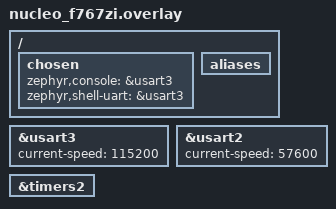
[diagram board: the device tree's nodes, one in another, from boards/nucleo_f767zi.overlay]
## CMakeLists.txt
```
# SPDX-License-Identifier: Apache-2.0

cmake_minimum_required(VERSION 3.20.0)
find_package(Zephyr REQUIRED HINTS $ENV{ZEPHYR_BASE})
project(EdgeSystemController)

set(BOARD_FLASH_RUNNER jlink)

FILE(GLOB app_sources src/*.c)
target_sources(app PRIVATE ${app_sources})
```

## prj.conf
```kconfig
CONFIG_STDOUT_CONSOLE=y

CONFIG_LOG=y
CONFIG_LOG_MODE_IMMEDIATE=y
CONFIG_LOG_PRINTK=y

# Kernel Configuration
CONFIG_MULTITHREADING=y
CONFIG_NUM_PREEMPT_PRIORITIES=15
CONFIG_MAIN_STACK_SIZE=2048
CONFIG_SYSTEM_WORKQUEUE_STACK_SIZE=2048
CONFIG_IDLE_STACK_SIZE=512

# Thread Configuration
CONFIG_THREAD_MONITOR=y
CONFIG_THREAD_NAME=y
CONFIG_THREAD_RUNTIME_STATS=y

# Message Queue Configuration
CONFIG_KERNEL_MEM_POOL=y

# Pipe Configuration  

# Ring Buffer Configuration
CONFIG_RING_BUFFER=y


# Memory Management
CONFIG_HEAP_MEM_POOL_SIZE=262144
CONFIG_DYNAMIC_THREAD=y

# Serial/UART for MAVLink
CONFIG_SERIAL=y
CONFIG_UART_INTERRUPT_DRIVEN=y
CONFIG_UART_LINE_CTRL=y

CONFIG_GPIO=y

# Debug Options
CONFIG_DEBUG=y
CONFIG_ASSERT=y
```

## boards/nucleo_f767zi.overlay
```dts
/*
 * Device Tree Overlay for STM32F767ZI Nucleo Board
 * Edge AI System Controller
 */


/ {
	chosen {
		zephyr,console = &usart3;
		zephyr,shell-uart = &usart3;
	};

	aliases {

	};
};

/* UART3 for console/debug */
&usart3 {
	status = "okay";
	current-speed = <115200>;
};

/* UART2 for MAVLink communication */
&usart2 {
	status = "okay";
	current-speed = <57600>;
};

&timers2 {

};
```

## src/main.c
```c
/**
 * SPDX-License-Identifier: Apache-2.0
 */

#include <zephyr/kernel.h>
#include <inttypes.h>
#include <zephyr/logging/log.h>

#include "system_config.h"
#include "device_fsm.h"
#include "common_types.h"
#include "ipc_config.h"
#include "thread_interface.h"

#define LOG_LEVEL CONFIG_MAIN_LOG_LEVEL
LOG_MODULE_REGISTER(main);

/*
 * GLOBAL STATE VARIABLES
 */
system_state_t system_state = INIT;
/* Global System State */
thread_health_t g_health = {0};
volatile bool g_system_running = false;


/**
 * IPC PRIMITIVES DEFINITIONS
 */

/* Message Queues */
K_MSGQ_DEFINE(sys_cmd_queue, sizeof(sys_command_t), SYS_CMD_QUEUE_SIZE, 4);
K_MSGQ_DEFINE(mavlink_tx_queue, sizeof(telemetry_data_t), MAVLINK_TX_QUEUE_SIZE, 4);

/**
 * THREAD DEFINITIONS
 */
/* Define Thread Stacks */
K_THREAD_STACK_DEFINE(mavlink_stack, MAVLINK_STACK_SIZE);
K_THREAD_STACK_DEFINE(sys_mgr_stack, SYS_MGR_STACK_SIZE);
K_THREAD_STACK_DEFINE(health_stack, HEALTH_STACK_SIZE);

/* Thread Control Blocks */
static struct k_thread mavlink_thread_data;
static struct k_thread sys_mgr_thread_data;
static struct k_thread health_thread_data;

/* Thread IDs */
static k_tid_t mavlink_tid;
static k_tid_t sys_mgr_tid;
static k_tid_t health_tid;

#define SLEEP_TIME_MS   1000

int main(void)
{
	LOG_INF("  Edge AI Vision System Controller\n");
	LOG_INF("  Platform: STM32F767ZI\n");
	LOG_INF("  Threads: 6 (SysMgr, MAVLink, AI, Video, GCS, Health)\n\n");

	/* All threads are auto-started by K_THREAD_DEFINE */
	/* Create MAVLink Thread */
    mavlink_tid = k_thread_create(&mavlink_thread_data, mavlink_stack,
                                   K_THREAD_STACK_SIZEOF(mavlink_stack),
                                   mavlink_thread,
                                   NULL, NULL, NULL,
                                   MAVLINK_PRIORITY, 0, K_NO_WAIT);
    k_thread_name_set(mavlink_tid, "mavlink");
    LOG_INF("Created: MAVLink Thread (Priority %d)", MAVLINK_PRIORITY);
    
    /* Create SysMgr Thread */
    sys_mgr_tid = k_thread_create(&sys_mgr_thread_data, sys_mgr_stack,
                                  K_THREAD_STACK_SIZEOF(sys_mgr_stack),
                                  sys_mgr_thread,
                                  NULL, NULL, NULL,
                                  SYS_MGR_PRIORITY, 0, K_NO_WAIT);
    k_thread_name_set(sys_mgr_tid, "sys_mgr");
    LOG_INF("Created: SysMgr Thread (Priority %d)", SYS_MGR_PRIORITY);
    
    /* Create Health Monitor Thread */
    health_tid = k_thread_create(&health_thread_data, health_stack,
                                  K_THREAD_STACK_SIZEOF(health_stack),
                                  health_thread,
                                  NULL, NULL, NULL,
                                  HEALTH_PRIORITY, 0, K_NO_WAIT);
    k_thread_name_set(health_tid, "health");
    LOG_INF("Created: Health Thread (Priority %d)", HEALTH_PRIORITY);

	while (1) {
		k_msleep(SLEEP_TIME_MS);
	}

	return 0;
}
```

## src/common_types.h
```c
/**
 * @file common_types.h
 * @brief Common data structures used across threads
 */

#ifndef COMMON_TYPES_H_
#define COMMON_TYPES_H_

#include <stdint.h>
#include <stdbool.h>
#include <zephyr/sys/atomic.h>
#include "system_config.h"

/**
 * COMMAND MESSAGES
 */

/* System Command Types */
typedef enum {
    CMD_STOP,
    CMD_START,
    CMD_STREAM_START,
    CMD_STREAM_STOP,
    CMD_SHUTDOWN,
    CMD_ERROR
} system_cmd_t;

/* System Command Structure */
typedef struct {
    system_cmd_t command;   /* Command type */
    uint32_t param;         /* Command parameter */
} sys_command_t;

/* Telemetry Data Structure */
typedef struct {
    float lat;          /* Latitude in degrees */
    float lon;          /* Longitude in degrees */
    float alt;          /* Altitude in meters */
    float roll;         /* Roll angle in degrees */
    float pitch;        /* Pitch angle in degrees */
    float yaw;          /* Yaw angle in degrees */
    uint32_t timestamp; /* System timestamp in ms */
} telemetry_data_t;


/* Thread Heartbeat Structure */
typedef struct {
    atomic_t mavlink_heartbeat;
    atomic_t sys_mgr_heartbeat;
} thread_health_t;

/* Thread IDs for health monitoring */
#define THREAD_SYS_MGR  0
#define THREAD_MAVLINK  1
#define THREAD_AI       2
#define THREAD_GCS      3
#define THREAD_HEALTH   4
#define NUM_THREADS     5

#endif /* COMMON_TYPES_H_ */
```

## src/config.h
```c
#ifndef CONFIG_H_
#define CONFIG_H_

#include <stdint.h>

typedef struct dev_data
{
    uint8_t _reserved;
} dev_data_t;

#endif /* CONFIG_H_ */
```

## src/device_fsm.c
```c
/**
 * @file device_fsm.c
 * @brief Internal device finite state machine implementation
 */ 
#include <zephyr/logging/log.h>

#include "device_fsm.h"

#define LOG_LEVEL CONFIG_DEVICE_SM_LOG_LEVEL
LOG_MODULE_REGISTER(device_sm);

static system_state_t current_state = INIT;
static system_state_t previous_state = INIT;

/**
 * @brief State machine initialization
 */
void fsm_init(void)
{
    current_state = INIT;
}

/**
 * @brief Get the current state of the state machine
 * @return The current system state
 */
system_state_t fsm_get_current_state(void)
{
    return current_state;
}

/**
 * @brief Get the previous state of the state machine
 * @param  NIL
 * @return The previous system state
 */
system_state_t fsm_get_previous_state(void)
{
    return previous_state;
}

/** 
 * @brief State transition function
 * @param event The event triggering the state transition
 */
void fsm_event_handler(system_event_t event) 
{
    previous_state = current_state;
    
    switch (current_state) {
        case INIT:
            if (event == EVENT_INIT_DONE) {
                current_state = IDLE;
                LOG_INF("Transition: INIT -> IDLE");
            }
            else if (event == EVENT_INIT_FAILED) {
                current_state = FAULT;
                LOG_INF("Transition: INIT -> FAULT");
            }
            break;
        case IDLE:
            if (event == EVENT_CMD_START) {
                current_state = ACTIVE;
                LOG_INF("Transition: IDLE -> ACTIVE");
            } 
            else if (event == EVENT_CMD_SHUTDOWN) {
                current_state = SHUTDOWN;
                LOG_INF("Transition: IDLE -> SHUTDOWN");
            }
            else if (event == EVENT_FAULT_DETECTED) {
                current_state = FAULT;
                LOG_INF("Transition: IDLE -> FAULT");
            }
            break;
        case ACTIVE:
            if (event == EVENT_STREAM_STARTED) {
                current_state = STREAMING;
                LOG_INF("Transition: ACTIVE -> STREAMING");
            } 
            else if (event == EVENT_CMD_STOP) {
                current_state = IDLE;
                LOG_INF("Transition: ACTIVE -> IDLE");
            }
            else if (event == EVENT_CMD_SHUTDOWN) {
                current_state = SHUTDOWN;
                LOG_INF("Transition: ACTIVE -> SHUTDOWN");
            }
            else if (event == EVENT_FAULT_DETECTED) {
                current_state = FAULT;
                LOG_INF("Transition: ACTIVE -> FAULT");
            }
            break;
        case STREAMING:
            if (event == EVENT_STREAM_DEGRADED) {
                current_state = DEGRADED;
                LOG_INF("Transition: STREAMING -> DEGRADED");
            } 
            else if (event == EVENT_STREAM_STOPPED) {
                current_state = ACTIVE;
                LOG_INF("Transition: STREAMING -> ACTIVE");
            }
            else if (event == EVENT_CMD_SHUTDOWN) {
                current_state = SHUTDOWN;
                LOG_INF("Transition: STREAMING -> SHUTDOWN");
            }
            else if (event == EVENT_FAULT_DETECTED) {
                current_state = FAULT;
                LOG_INF("Transition: STREAMING -> FAULT");
            }
            break;
        case DEGRADED:
            if (event == EVENT_STREAM_RECOVERED) {
                current_state = STREAMING;
                LOG_INF("Transition: DEGRADED -> STREAMING");
            } 
            else if (event == EVENT_STREAM_STOPPED) {
                current_state = ACTIVE;
                LOG_INF("Transition: DEGRADED -> ACTIVE");
            }
            else if (event == EVENT_CMD_SHUTDOWN) {
                current_state = SHUTDOWN;
                LOG_INF("Transition: DEGRADED -> SHUTDOWN");
            }
            else if (event == EVENT_FAULT_DETECTED) {
                current_state = FAULT;
                LOG_INF("Transition: DEGRADED -> FAULT");
            }
            break;     
        case FAULT:
            if (event == EVENT_FAULT_RECOVERED) {
                current_state = IDLE;
                LOG_INF("Transition: FAULT -> IDLE");
            }
            break;
        case SHUTDOWN:
            // No transitions out of SHUTDOWN in this simple model
            break;
        default:
            LOG_INF("Unknown state: %d", current_state);
            break;
    }
}
```

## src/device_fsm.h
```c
/**
 * @file device_fsm.h
 * @brief Internal device finite state machine definitions
 */

#ifndef DEVICE_FSM_H_
#define DEVICE_FSM_H_

/* List of end node states */
typedef enum {
    INIT, 
    IDLE,
    ACTIVE,
    STREAMING,
    DEGRADED,
    SHUTDOWN,
    FAULT
} system_state_t;

// Define events
typedef enum {
    EVENT_INIT_DONE,
    EVENT_INIT_FAILED,
    EVENT_CMD_START,
    EVENT_CMD_STOP,
    EVENT_CMD_SHUTDOWN,
    EVENT_STREAM_STARTED,
    EVENT_STREAM_STOPPED,
    EVENT_STREAM_DEGRADED,
    EVENT_STREAM_RECOVERED,
    EVENT_FAULT_DETECTED,
    EVENT_FAULT_RECOVERED
} system_event_t;

void fsm_init(void);
system_state_t fsm_get_current_state(void);
system_state_t fsm_get_previous_state(void);
void fsm_event_handler(system_event_t event);

#endif /* DEVICE_FSM_H_ */
```

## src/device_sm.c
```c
// State machine includes
//#include <zephyr/smf.h>
#include <zephyr/logging/log.h>

#include "device_sm.h"

#define LOG_LEVEL CONFIG_DEVICE_SM_LOG_LEVEL
LOG_MODULE_REGISTER(device_sm);

static state_t current_state = INIT;
static state_t previous_state = INIT;

void fsm_init(void)
{
    current_state = INIT;
}

state_t fsm_get_current_state(void)
{
    return current_state;
}

state_t fsm_get_previous_state(void)
{
    return previous_state;
}


// State transition function
void fsm_event_handler(event_t event) 
{
    previous_state = current_state;
    
    switch (current_state) {
        case INIT:
            if (event == EVENT_INIT_DONE) {
                current_state = IDLE;
                LOG_INF("Transition: INIT -> IDLE");
            }
            else if (event == EVENT_INIT_FAILED) {
                current_state = FAULT;
                LOG_INF("Transition: INIT -> FAULT");
            }
            break;
        case IDLE:
            if (event == EVENT_CMD_START) {
                current_state = ACTIVE;
                LOG_INF("Transition: IDLE -> ACTIVE");
            } 
            else if (event == EVENT_CMD_SHUTDOWN) {
                current_state = SHUTDOWN;
                LOG_INF("Transition: IDLE -> SHUTDOWN");
            }
            else if (event == EVENT_FAULT_DETECTED) {
                current_state = FAULT;
                LOG_INF("Transition: IDLE -> FAULT");
            }
            break;
        case ACTIVE:
            if (event == EVENT_STREAM_STARTED) {
                current_state = STREAMING;
                LOG_INF("Transition: ACTIVE -> STREAMING");
            } 
            else if (event == EVENT_CMD_STOP) {
                current_state = IDLE;
                LOG_INF("Transition: ACTIVE -> IDLE");
            }
            else if (event == EVENT_CMD_SHUTDOWN) {
                current_state = SHUTDOWN;
                LOG_INF("Transition: ACTIVE -> SHUTDOWN");
            }
            else if (event == EVENT_FAULT_DETECTED) {
                current_state = FAULT;
                LOG_INF("Transition: ACTIVE -> FAULT");
            }
            break;
        case STREAMING:
            if (event == EVENT_STREAM_DEGRADED) {
                current_state = DEGRADED;
                LOG_INF("Transition: STREAMING -> DEGRADED");
            } 
            else if (event == EVENT_STREAM_STOPPED) {
                current_state = ACTIVE;
                LOG_INF("Transition: STREAMING -> ACTIVE");
            }
            else if (event == EVENT_CMD_SHUTDOWN) {
                current_state = SHUTDOWN;
                LOG_INF("Transition: STREAMING -> SHUTDOWN");
            }
            else if (event == EVENT_FAULT_DETECTED) {
                current_state = FAULT;
                LOG_INF("Transition: STREAMING -> FAULT");
            }
            break;
        case DEGRADED:
            if (event == EVENT_STREAM_RECOVERED) {
                current_state = STREAMING;
                LOG_INF("Transition: DEGRADED -> STREAMING");
            } 
            else if (event == EVENT_STREAM_STOPPED) {
                current_state = ACTIVE;
                LOG_INF("Transition: DEGRADED -> ACTIVE");
            }
            else if (event == EVENT_CMD_SHUTDOWN) {
                current_state = SHUTDOWN;
                LOG_INF("Transition: DEGRADED -> SHUTDOWN");
            }
            else if (event == EVENT_FAULT_DETECTED) {
                current_state = FAULT;
                LOG_INF("Transition: DEGRADED -> FAULT");
            }
            break;     
        case FAULT:
            if (event == EVENT_FAULT_RECOVERED) {
                current_state = IDLE;
                LOG_INF("Transition: FAULT -> IDLE");
            }
            break;
        case SHUTDOWN:
            LOG_INF("System in SHUTDOWN state - restart required");
            break;
        default:
            LOG_INF("Unknown state: %d", current_state);
            break;
    }
}
```

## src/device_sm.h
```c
#ifndef DEVICE_SM_H_
#define DEVICE_SM_H_

/* List of end node states */
typedef enum {
    INIT, 
    IDLE,
    ACTIVE,
    STREAMING,
    DEGRADED,
    SHUTDOWN,
    FAULT
} state_t;

// Define events
typedef enum {
    EVENT_INIT_DONE,
    EVENT_INIT_FAILED,
    EVENT_CMD_START,
    EVENT_CMD_STOP,
    EVENT_CMD_SHUTDOWN,
    EVENT_STREAM_STARTED,
    EVENT_STREAM_STOPPED,
    EVENT_STREAM_DEGRADED,
    EVENT_STREAM_RECOVERED,
    EVENT_FAULT_DETECTED,
    EVENT_FAULT_RECOVERED
} event_t;

void fsm_init(void);
state_t fsm_get_current_state(void);
state_t fsm_get_previous_state(void);
void fsm_event_handler(event_t event);

#endif /* DEVICE_SM_H_ */
```

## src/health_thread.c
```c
/**
 * @file health_thread.c
 * @brief Health monitoring thread implementation
 * @details Monitors all threads and triggers recovery on failures
 */

#include <zephyr/kernel.h>
#include <zephyr/drivers/gpio.h>
#include <zephyr/logging/log.h>

#include "system_config.h"
#include "common_types.h"
#include "ipc_config.h"

#define LOG_LEVEL CONFIG_HEALTH_THREAD_LOG_LEVEL
LOG_MODULE_REGISTER(health_thread);

#define LED0_NODE DT_ALIAS(led0)

static const struct gpio_dt_spec led = GPIO_DT_SPEC_GET(LED0_NODE, gpios);

/**
 * @brief Health Monitor Thread Main Loop
 * @details
 * - Checks all thread heartbeats every 500ms
 * - Detects thread hangs/failures
 * - Triggers recovery via system commands
 * 
 * @param p1 Unused parameter
 * @param p2 Unused parameter
 * @param p3 Unused parameter
 */
void health_thread(void *p1, void *p2, void *p3)
{
    static thread_health_t last_health = {0};
    sys_command_t error_cmd;
    uint32_t check_count = 0;
    
    ARG_UNUSED(p1);
    ARG_UNUSED(p2);
    ARG_UNUSED(p3);
    
    LOG_INF("[Health] Thread started");
    LOG_INF("[Health] Monitoring period: %dms", HEALTH_CHECK_PERIOD_MS);

    int ret;
	bool led_state = true;

	if (!gpio_is_ready_dt(&led)) {
		LOG_ERR("LED device not ready");
	} else {
        ret = gpio_pin_configure_dt(&led, GPIO_OUTPUT_ACTIVE);
        if (ret < 0) {
            LOG_ERR("Error configuring LED pin");
        }
    }

    while (1) {
        /* Wait for health check interval */
        k_msleep(HEALTH_CHECK_PERIOD_MS);
        check_count++;
        
		ret = gpio_pin_toggle_dt(&led);
		if (ret < 0) {
			LOG_ERR("Error toggling LED pin");
		}
		led_state = !led_state;


        bool all_healthy = true;
        
        // Atomic snapshot ensures consistent view of all counters
        atomic_val_t mavlink_hb = atomic_get(&g_health.mavlink_heartbeat);
        atomic_val_t last_mavlink_hb = atomic_get(&last_health.mavlink_heartbeat);  
        
        /* Check MAVLink thread */
        if (mavlink_hb == last_mavlink_hb) {
            LOG_ERR("[Health] ERROR: MAVLink thread HUNG!");
            all_healthy = false;
        }

        atomic_val_t sys_mgr_hb = atomic_get(&g_health.sys_mgr_heartbeat);
        atomic_val_t last_sys_mgr_hb = atomic_get(&last_health.sys_mgr_heartbeat);
        
        /* Check SysMgr thread */
        if (sys_mgr_hb == last_sys_mgr_hb) {
            LOG_ERR("[Health] ERROR: Sys_Mgr thread HUNG!");
            all_healthy = false;
        }
        
        if (!all_healthy) {
            /* Trigger error recovery */
            error_cmd.command = CMD_ERROR;
            error_cmd.param = check_count;
            k_msgq_put(&sys_cmd_queue, &error_cmd, K_NO_WAIT);
            
            LOG_INF("[Health] Recovery command sent");
        } else {
            /* Periodic status report (every 10 checks = 5 seconds) */
            if (check_count % 10 == 0) {
                LOG_INF("[Health] All threads OK (check #%u)", check_count);
                LOG_INF("[Health]   MAVLink: %u, SysMgr: %u",
                       (uint32_t)mavlink_hb,
                       (uint32_t)sys_mgr_hb);
            }
        }
        
        /* Save current state for next comparison */
        last_health = g_health;
    }
}
```

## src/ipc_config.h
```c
/**
 * @file ipc_config.h
 * @brief Inter-Process Communication configuration
 */

#ifndef IPC_CONFIG_H
#define IPC_CONFIG_H

#include <zephyr/kernel.h>

#include "common_types.h"
#include "system_config.h"
#include "device_fsm.h"

/* MESSAGE QUEUE DECLARATIONS */
extern struct k_msgq mavlink_tx_queue;
extern struct k_msgq sys_cmd_queue;

/* GLOBAL STATE */
extern system_state_t system_state;

/* External Global State */
extern thread_health_t g_health;
extern volatile bool g_system_running;


/* UTILITY FUNCTIONS */
void update_thread_heartbeat(uint8_t thread_id);

#endif /* IPC_CONFIG_H */
```

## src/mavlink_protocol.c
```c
/**
 * @file mavlink_protocol.c
 * @brief MAVLink protocol implementation
 */

#include <zephyr/kernel.h>
#include <zephyr/drivers/uart.h>
#include <string.h>
#include "mavlink_protocol.h"

/* MAVLink CRC Extra values (per message ID) */
static const uint8_t mavlink_crc_extra[] = {
    [MAVLINK_MSG_ID_HEARTBEAT] = 50,
    [MAVLINK_MSG_ID_COMMAND_LONG] = 152,
    [MAVLINK_MSG_ID_COMMAND_ACK] = 143,
    [MAVLINK_MSG_ID_STATUSTEXT] = 83,
};

/* X.25 CRC calculation */
static const uint16_t crc_table[256] = {
    0x0000, 0x1189, 0x2312, 0x329b, 0x4624, 0x57ad, 0x6536, 0x74bf,
    0x8c48, 0x9dc1, 0xaf5a, 0xbed3, 0xca6c, 0xdbe5, 0xe97e, 0xf8f7,
    0x1081, 0x0108, 0x3393, 0x221a, 0x56a5, 0x472c, 0x75b7, 0x643e,
    0x9cc9, 0x8d40, 0xbfdb, 0xae52, 0xdaed, 0xcb64, 0xf9ff, 0xe876,
    0x2102, 0x308b, 0x0210, 0x1399, 0x6726, 0x76af, 0x4434, 0x55bd,
    0xad4a, 0xbcc3, 0x8e58, 0x9fd1, 0xeb6e, 0xfae7, 0xc87c, 0xd9f5,
    0x3183, 0x200a, 0x1291, 0x0318, 0x77a7, 0x662e, 0x54b5, 0x453c,
    0xbdcb, 0xac42, 0x9ed9, 0x8f50, 0xfbef, 0xea66, 0xd8fd, 0xc974,
    0x4204, 0x538d, 0x6116, 0x709f, 0x0420, 0x15a9, 0x2732, 0x36bb,
    0xce4c, 0xdfc5, 0xed5e, 0xfcd7, 0x8868, 0x99e1, 0xab7a, 0xbaf3,
    0x5285, 0x430c, 0x7197, 0x601e, 0x14a1, 0x0528, 0x37b3, 0x263a,
    0xdecd, 0xcf44, 0xfddf, 0xec56, 0x98e9, 0x8960, 0xbbfb, 0xaa72,
    0x6306, 0x728f, 0x4014, 0x519d, 0x2522, 0x34ab, 0x0630, 0x17b9,
    0xef4e, 0xfec7, 0xcc5c, 0xddd5, 0xa96a, 0xb8e3, 0x8a78, 0x9bf1,
    0x7387, 0x620e, 0x5095, 0x411c, 0x35a3, 0x242a, 0x16b1, 0x0738,
    0xffcf, 0xee46, 0xdcdd, 0xcd54, 0xb9eb, 0xa862, 0x9af9, 0x8b70,
    0x8408, 0x9581, 0xa71a, 0xb693, 0xc22c, 0xd3a5, 0xe13e, 0xf0b7,
    0x0840, 0x19c9, 0x2b52, 0x3adb, 0x4e64, 0x5fed, 0x6d76, 0x7cff,
    0x9489, 0x8500, 0xb79b, 0xa612, 0xd2ad, 0xc324, 0xf1bf, 0xe036,
    0x18c1, 0x0948, 0x3bd3, 0x2a5a, 0x5ee5, 0x4f6c, 0x7df7, 0x6c7e,
    0xa50a, 0xb483, 0x8618, 0x9791, 0xe32e, 0xf2a7, 0xc03c, 0xd1b5,
    0x2942, 0x38cb, 0x0a50, 0x1bd9, 0x6f66, 0x7eef, 0x4c74, 0x5dfd,
    0xb58b, 0xa402, 0x9699, 0x8710, 0xf3af, 0xe226, 0xd0bd, 0xc134,
    0x39c3, 0x284a, 0x1ad1, 0x0b58, 0x7fe7, 0x6e6e, 0x5cf5, 0x4d7c,
    0xc60c, 0xd785, 0xe51e, 0xf497, 0x8028, 0x91a1, 0xa33a, 0xb2b3,
    0x4a44, 0x5bcd, 0x6956, 0x78df, 0x0c60, 0x1de9, 0x2f72, 0x3efb,
    0xd68d, 0xc704, 0xf59f, 0xe416, 0x90a9, 0x8120, 0xb3bb, 0xa232,
    0x5ac5, 0x4b4c, 0x79d7, 0x685e, 0x1ce1, 0x0d68, 0x3ff3, 0x2e7a,
    0xe70e, 0xf687, 0xc41c, 0xd595, 0xa12a, 0xb0a3, 0x8238, 0x93b1,
    0x6b46, 0x7acf, 0x4854, 0x59dd, 0x2d62, 0x3ceb, 0x0e70, 0x1ff9,
    0xf78f, 0xe606, 0xd49d, 0xc514, 0xb1ab, 0xa022, 0x92b9, 0x8330,
    0x7bc7, 0x6a4e, 0x58d5, 0x495c, 0x3de3, 0x2c6a, 0x1ef1, 0x0f78
};

/**
 * @brief Initialize MAVLink parser
 */
void mavlink_parser_init(mavlink_parser_t *parser)
{
    memset(parser, 0, sizeof(mavlink_parser_t));
    parser->state = MAVLINK_PARSE_STATE_IDLE;
    parser->seq = 0;
}

/**
 * @brief Accumulate CRC byte
 */
void mavlink_crc_accumulate(uint8_t data, uint16_t *crc)
{
    uint8_t tmp = data ^ (*crc & 0xff);
    *crc = (*crc >> 8) ^ crc_table[tmp];
}

/**
 * @brief Calculate CRC for buffer
 */
uint16_t mavlink_crc_calculate(const uint8_t *buf, uint16_t len)
{
    uint16_t crc = 0xFFFF;
    for (uint16_t i = 0; i < len; i++) {
        mavlink_crc_accumulate(buf[i], &crc);
    }
    return crc;
}

/**
 * @brief Finalize CRC with message-specific extra byte
 */
uint16_t mavlink_finalize_crc(uint16_t crc, uint8_t msgid)
{
    if (msgid < sizeof(mavlink_crc_extra)) {
        mavlink_crc_accumulate(mavlink_crc_extra[msgid], &crc);
    }
    return crc;
}

/**
 * @brief Parse single MAVLink byte
 * @return true if complete message received
 */
bool mavlink_parse_byte(mavlink_parser_t *parser, uint8_t byte, 
                        mavlink_message_t *msg_out)
{
    bool msg_received = false;

    switch (parser->state) {
        case MAVLINK_PARSE_STATE_IDLE:
            if (byte == MAVLINK_STX) {
                parser->state = MAVLINK_PARSE_STATE_GOT_STX;
                parser->msg.magic = byte;
                parser->crc = 0xFFFF;
            }
            break;

        case MAVLINK_PARSE_STATE_GOT_STX:
            parser->msg.len = byte;
            parser->payload_idx = 0;
            mavlink_crc_accumulate(byte, &parser->crc);
            parser->state = MAVLINK_PARSE_STATE_GOT_LENGTH;
            break;

        case MAVLINK_PARSE_STATE_GOT_LENGTH:
            parser->msg.seq = byte;
            mavlink_crc_accumulate(byte, &parser->crc);
            parser->state = MAVLINK_PARSE_STATE_GOT_SEQ;
            break;

        case MAVLINK_PARSE_STATE_GOT_SEQ:
            parser->msg.sysid = byte;
            mavlink_crc_accumulate(byte, &parser->crc);
            parser->state = MAVLINK_PARSE_STATE_GOT_SYSID;
            break;

        case MAVLINK_PARSE_STATE_GOT_SYSID:
            parser->msg.compid = byte;
            mavlink_crc_accumulate(byte, &parser->crc);
            parser->state = MAVLINK_PARSE_STATE_GOT_COMPID;
            break;

        case MAVLINK_PARSE_STATE_GOT_COMPID:
            parser->msg.msgid = byte;
            mavlink_crc_accumulate(byte, &parser->crc);
            if (parser->msg.len == 0) {
                parser->state = MAVLINK_PARSE_STATE_GOT_PAYLOAD;
            } else {
                parser->state = MAVLINK_PARSE_STATE_GOT_MSGID;
            }
            break;

        case MAVLINK_PARSE_STATE_GOT_MSGID:
            parser->msg.payload[parser->payload_idx++] = byte;
            mavlink_crc_accumulate(byte, &parser->crc);
            if (parser->payload_idx >= parser->msg.len) {
                parser->state = MAVLINK_PARSE_STATE_GOT_PAYLOAD;
            }
            break;

        case MAVLINK_PARSE_STATE_GOT_PAYLOAD:
            parser->msg.checksum = byte;  /* Low byte */
            parser->state = MAVLINK_PARSE_STATE_GOT_CRC1;
            break;

        case MAVLINK_PARSE_STATE_GOT_CRC1:
            parser->msg.checksum |= (uint16_t)byte << 8;  /* High byte */
            
            /* Finalize CRC with extra byte */
            uint16_t calc_crc = mavlink_finalize_crc(parser->crc, 
                                                     parser->msg.msgid);
            
            if (calc_crc == parser->msg.checksum) {
                /* Valid message received */
                if (msg_out) {
                    memcpy(msg_out, &parser->msg, sizeof(mavlink_message_t));
                }
                msg_received = true;
            }
            
            /* Reset parser for next message */
            parser->state = MAVLINK_PARSE_STATE_IDLE;
            break;
    }

    return msg_received;
}

/**
 * @brief Send MAVLink HEARTBEAT message
 */
int mavlink_send_heartbeat(const struct device *uart)
{
    uint8_t buf[MAVLINK_FRAME_MAX_SIZE];
    mavlink_heartbeat_t hb = {
        .custom_mode = 0,
        .type = 6,  /* MAV_TYPE_GCS */
        .autopilot = 8,  /* MAV_AUTOPILOT_INVALID */
        .base_mode = MAV_MODE_FLAG_CUSTOM_MODE_ENABLED,
        .system_status = MAV_STATE_ACTIVE,
        .mavlink_version = 3
    };

    static uint8_t seq = 0;
    
    buf[0] = MAVLINK_STX;
    buf[1] = sizeof(mavlink_heartbeat_t);
    buf[2] = seq++;
    buf[3] = MAVLINK_SYSID_CONTROLLER;
    buf[4] = MAVLINK_COMPID_CONTROLLER;
    buf[5] = MAVLINK_MSG_ID_HEARTBEAT;
    
    memcpy(&buf[6], &hb, sizeof(mavlink_heartbeat_t));
    
    uint16_t crc = mavlink_crc_calculate(&buf[1], sizeof(mavlink_heartbeat_t) + 5);
    crc = mavlink_finalize_crc(crc, MAVLINK_MSG_ID_HEARTBEAT);
    
    buf[6 + sizeof(mavlink_heartbeat_t)] = crc & 0xFF;
    buf[7 + sizeof(mavlink_heartbeat_t)] = (crc >> 8) & 0xFF;
    
    int len = 8 + sizeof(mavlink_heartbeat_t);
    
    for (int i = 0; i < len; i++) {
        uart_poll_out(uart, buf[i]);
    }
    
    return len;
}

/**
 * @brief Send MAVLink COMMAND_ACK message
 */
int mavlink_send_command_ack(const struct device *uart, uint16_t command, 
                             uint8_t result, uint8_t target_sys, 
                             uint8_t target_comp)
{
    uint8_t buf[MAVLINK_FRAME_MAX_SIZE];
    mavlink_command_ack_t ack = {
        .command = command,
        .result = result,
        .progress = 0,
        .result_param2 = 0,
        .target_system = target_sys,
        .target_component = target_comp
    };

    static uint8_t seq = 0;
    
    buf[0] = MAVLINK_STX;
    buf[1] = sizeof(mavlink_command_ack_t);
    buf[2] = seq++;
    buf[3] = MAVLINK_SYSID_CONTROLLER;
    buf[4] = MAVLINK_COMPID_CONTROLLER;
    buf[5] = MAVLINK_MSG_ID_COMMAND_ACK;
    
    memcpy(&buf[6], &ack, sizeof(mavlink_command_ack_t));
    
    uint16_t crc = mavlink_crc_calculate(&buf[1], sizeof(mavlink_command_ack_t) + 5);
    crc = mavlink_finalize_crc(crc, MAVLINK_MSG_ID_COMMAND_ACK);
    
    buf[6 + sizeof(mavlink_command_ack_t)] = crc & 0xFF;
    buf[7 + sizeof(mavlink_command_ack_t)] = (crc >> 8) & 0xFF;
    
    int len = 8 + sizeof(mavlink_command_ack_t);
    
    for (int i = 0; i < len; i++) {
        uart_poll_out(uart, buf[i]);
    }
    
    return len;
}

/**
 * @brief Send MAVLink STATUSTEXT message
 */
int mavlink_send_statustext(const struct device *uart, const char *text, 
                            uint8_t severity)
{
    uint8_t buf[MAVLINK_FRAME_MAX_SIZE];
    uint8_t payload[54] = {0};  /* severity(1) + text(50) + id(2) + chunk_seq(1) */
    
    payload[0] = severity;
    strncpy((char *)&payload[1], text, 50);
    
    static uint8_t seq = 0;
    
    buf[0] = MAVLINK_STX;
    buf[1] = 54;
    buf[2] = seq++;
    buf[3] = MAVLINK_SYSID_CONTROLLER;
    buf[4] = MAVLINK_COMPID_CONTROLLER;
    buf[5] = MAVLINK_MSG_ID_STATUSTEXT;
    
    memcpy(&buf[6], payload, 54);
    
    uint16_t crc = mavlink_crc_calculate(&buf[1], 54 + 5);
    crc = mavlink_finalize_crc(crc, MAVLINK_MSG_ID_STATUSTEXT);
    
    buf[60] = crc & 0xFF;
    buf[61] = (crc >> 8) & 0xFF;
    
    for (int i = 0; i < 62; i++) {
        uart_poll_out(uart, buf[i]);
    }
    
    return 62;
}
```

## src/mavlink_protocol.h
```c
/**
 * @file mavlink_protocol.h
 * @brief MAVLink protocol definitions and message structures
 */

#ifndef MAVLINK_PROTOCOL_H_
#define MAVLINK_PROTOCOL_H_

#include <stdint.h>
#include <stdbool.h>

/* MAVLink Protocol Constants */
#define MAVLINK_STX                 0xFE    /* MAVLink v1 start byte */
#define MAVLINK_STX_V2              0xFD    /* MAVLink v2 start byte */
#define MAVLINK_MAX_PAYLOAD_LEN     255
#define MAVLINK_FRAME_MAX_SIZE      280

/* System and Component IDs */
#define MAVLINK_SYSID_CONTROLLER    1       /* This system */
#define MAVLINK_COMPID_CONTROLLER   1       /* This component */
#define MAVLINK_SYSID_DRONE         2       /* Drone system ID */

/* MAVLink Message IDs (simplified subset) */
#define MAVLINK_MSG_ID_HEARTBEAT            0
#define MAVLINK_MSG_ID_COMMAND_LONG         76
#define MAVLINK_MSG_ID_COMMAND_ACK          77
#define MAVLINK_MSG_ID_STATUSTEXT           253

/* MAV_CMD - Command definitions */
#define MAV_CMD_DO_SET_MODE                 176
#define MAV_CMD_USER_1                      31010  /* System START */
#define MAV_CMD_USER_2                      31011  /* System STOP */
#define MAV_CMD_USER_3                      31012  /* Stream START */
#define MAV_CMD_USER_4                      31013  /* Stream STOP */
#define MAV_CMD_USER_5                      31014  /* System SHUTDOWN */

/* MAV_RESULT - Command result codes */
#define MAV_RESULT_ACCEPTED                 0
#define MAV_RESULT_TEMPORARILY_REJECTED     1
#define MAV_RESULT_DENIED                   2
#define MAV_RESULT_UNSUPPORTED              3
#define MAV_RESULT_FAILED                   4
#define MAV_RESULT_IN_PROGRESS              5

/* MAV_STATE */
#define MAV_STATE_ACTIVE                    4

/* MAV_MODE_FLAG */
#define MAV_MODE_FLAG_CUSTOM_MODE_ENABLED   1

/* Parser States */
typedef enum {
    MAVLINK_PARSE_STATE_IDLE = 0,
    MAVLINK_PARSE_STATE_GOT_STX,
    MAVLINK_PARSE_STATE_GOT_LENGTH,
    MAVLINK_PARSE_STATE_GOT_SEQ,
    MAVLINK_PARSE_STATE_GOT_SYSID,
    MAVLINK_PARSE_STATE_GOT_COMPID,
    MAVLINK_PARSE_STATE_GOT_MSGID,
    MAVLINK_PARSE_STATE_GOT_PAYLOAD,
    MAVLINK_PARSE_STATE_GOT_CRC1
} mavlink_parse_state_t;

/* MAVLink Message Structure */
typedef struct {
    uint8_t magic;              /* STX */
    uint8_t len;                /* Payload length */
    uint8_t seq;                /* Sequence number */
    uint8_t sysid;              /* System ID */
    uint8_t compid;             /* Component ID */
    uint8_t msgid;              /* Message ID */
    uint8_t payload[MAVLINK_MAX_PAYLOAD_LEN];
    uint16_t checksum;          /* CRC */
} __attribute__((packed)) mavlink_message_t;

/* MAVLink HEARTBEAT Message */
typedef struct {
    uint32_t custom_mode;
    uint8_t type;
    uint8_t autopilot;
    uint8_t base_mode;
    uint8_t system_status;
    uint8_t mavlink_version;
} __attribute__((packed)) mavlink_heartbeat_t;

/* MAVLink COMMAND_LONG Message */
typedef struct {
    float param1;
    float param2;
    float param3;
    float param4;
    float param5;
    float param6;
    float param7;
    uint16_t command;
    uint8_t target_system;
    uint8_t target_component;
    uint8_t confirmation;
} __attribute__((packed)) mavlink_command_long_t;

/* MAVLink COMMAND_ACK Message */
typedef struct {
    uint16_t command;
    uint8_t result;
    uint8_t progress;
    int32_t result_param2;
    uint8_t target_system;
    uint8_t target_component;
} __attribute__((packed)) mavlink_command_ack_t;

/* MAVLink Parser Context */
typedef struct {
    mavlink_parse_state_t state;
    mavlink_message_t msg;
    uint16_t payload_idx;
    uint16_t crc;
    uint8_t seq;                /* Sequence counter for TX */
} mavlink_parser_t;

/* Function Prototypes */
void mavlink_parser_init(mavlink_parser_t *parser);
bool mavlink_parse_byte(mavlink_parser_t *parser, uint8_t byte, 
                        mavlink_message_t *msg_out);
uint16_t mavlink_crc_calculate(const uint8_t *buf, uint16_t len);
void mavlink_crc_accumulate(uint8_t data, uint16_t *crc);
uint16_t mavlink_finalize_crc(uint16_t crc, uint8_t msgid);

int mavlink_send_heartbeat(const struct device *uart);
int mavlink_send_command_ack(const struct device *uart, uint16_t command, 
                             uint8_t result, uint8_t target_sys, 
                             uint8_t target_comp);
int mavlink_send_statustext(const struct device *uart, const char *text, 
                            uint8_t severity);

#endif /* MAVLINK_PROTOCOL_H_ */
```

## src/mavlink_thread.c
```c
/**
 * @file mavlink_thread.c
 * @brief MAVLink communication thread implementation
 * @details Handles telemetry reception, command processing, and AI result forwarding
 */

#include <zephyr/kernel.h>
#include <string.h>
#include <zephyr/drivers/uart.h>
#include <zephyr/sys/ring_buffer.h>
#include <zephyr/logging/log.h>

#include "system_config.h"
#include "common_types.h"
#include "ipc_config.h"
#include "mavlink_protocol.h"


#define LOG_LEVEL CONFIG_MAVLINK_THREAD_LOG_LEVEL
LOG_MODULE_REGISTER(mavlink_thread);

/* UART Device */
#define UART_DEVICE_NODE DT_NODELABEL(usart2)

/* Ring buffer for UART RX */
#define UART_RX_RING_BUF_SIZE 512
RING_BUF_DECLARE(uart_rx_ring_buf, UART_RX_RING_BUF_SIZE);

/* MAVLink Parser */
static mavlink_parser_t mavlink_parser;

/* UART Device Handle */
static const struct device *uart_dev;

/* Heartbeat timing */
#define HEARTBEAT_PERIOD_MS 1000
static uint32_t last_heartbeat_time = 0;

/**
 * @brief UART Interrupt Callback
 * @details Called when UART receives data or TX is ready
 */
static void uart_isr_callback(const struct device *dev, void *user_data)
{
    ARG_UNUSED(user_data);
    
    if (!uart_irq_update(dev)) {
        return;
    }
    
    /* Handle RX data */
    if (uart_irq_rx_ready(dev)) {
        uint8_t byte;
        int rx_len;
        
        while ((rx_len = uart_fifo_read(dev, &byte, 1)) > 0) {
            /* Put byte into ring buffer */
            ring_buf_put(&uart_rx_ring_buf, &byte, 1);
        }
    }
}
/**
 * @brief Process received MAVLink command
 * @param msg Received MAVLink message
 * @return Result code for ACK
 */
static uint8_t process_mavlink_command(const mavlink_message_t *msg)
{
    if (msg->msgid != MAVLINK_MSG_ID_COMMAND_LONG) {
        return MAV_RESULT_UNSUPPORTED;
    }
    
    mavlink_command_long_t cmd;
    memcpy(&cmd, msg->payload, sizeof(mavlink_command_long_t));
    
    /* Check if command is for this system */
    if (cmd.target_system != MAVLINK_SYSID_CONTROLLER &&
        cmd.target_system != 0) {  /* 0 = broadcast */
        return MAV_RESULT_DENIED;
    }
    
    sys_command_t sys_cmd;
    sys_cmd.param = 0;
    uint8_t result = MAV_RESULT_ACCEPTED;
    
    LOG_INF("[MAVLink] Received command %u from sys=%u comp=%u\n",
           cmd.command, msg->sysid, msg->compid);
    
    /* Map MAVLink command to system command */
    switch (cmd.command) {
        case MAV_CMD_USER_1:  /* System START */
            sys_cmd.command = CMD_START;
            LOG_INF("[MAVLink] Command: START system");
            break;
            
        case MAV_CMD_USER_2:  /* System STOP */
            sys_cmd.command = CMD_STOP;
            LOG_INF("[MAVLink] Command: STOP system");
            break;
            
        case MAV_CMD_USER_3:  /* Stream START */
            sys_cmd.command = CMD_STREAM_START;
            LOG_INF("[MAVLink] Command: START video streaming");
            break;
            
        case MAV_CMD_USER_4:  /* Stream STOP */
            sys_cmd.command = CMD_STREAM_STOP;
            LOG_INF("[MAVLink] Command: STOP video streaming");
            break;
            
        case MAV_CMD_USER_5:  /* System SHUTDOWN */
            sys_cmd.command = CMD_SHUTDOWN;
            LOG_INF("[MAVLink] Command: SHUTDOWN system");
            break;
            
        default:
            LOG_INF("[MAVLink] Unsupported command: %u", cmd.command);
            result = MAV_RESULT_UNSUPPORTED;
            return result;
    }
    
    /* Put command into system command queue */
    if (k_msgq_put(&sys_cmd_queue, &sys_cmd, K_NO_WAIT) != 0) {
        LOG_ERR("[MAVLink] ERROR: System command queue full!");
        result = MAV_RESULT_TEMPORARILY_REJECTED;
    } else {
        LOG_INF("[MAVLink] Command queued successfully");
    }
    
    return result;
}


/**
 * @brief MAVLink Thread Main Loop
 * @details
 * - Receives telemetry from drone controller at 50Hz
 * - Processes system commands from drone
 * - Forwards AI detection results to drone controller
 * 
 * @param p1 Unused parameter
 * @param p2 Unused parameter
 * @param p3 Unused parameter
 */
void mavlink_thread(void *p1, void *p2, void *p3)
{
    mavlink_message_t msg;
    uint8_t byte;
    
    ARG_UNUSED(p1);
    ARG_UNUSED(p2);
    ARG_UNUSED(p3);
    
    LOG_INF("[MAVLink] Thread started\n");

    
    /* Get UART device */
    uart_dev = DEVICE_DT_GET(UART_DEVICE_NODE);
    if (!device_is_ready(uart_dev)) {
        LOG_ERR("[MAVLink] ERROR: UART device not ready!");
        return;
    }
    
    LOG_INF("[MAVLink] UART2 device ready");

    /* Initialize MAVLink parser */
    mavlink_parser_init(&mavlink_parser);
    
    /* Configure UART interrupt */
    uart_irq_callback_user_data_set(uart_dev, uart_isr_callback, NULL);
    uart_irq_rx_enable(uart_dev);
    
    LOG_INF("[MAVLink] UART2 interrupt enabled");
    
    /* Send initial heartbeat */
    mavlink_send_heartbeat(uart_dev);
    mavlink_send_statustext(uart_dev, "System Controller Online", 6);
    last_heartbeat_time = k_uptime_get_32();   
    
    while (1) {
        /* Update heartbeat */
        atomic_inc(&g_health.mavlink_heartbeat);
        
        /* Check for system commands from drone controller */
        /* Process received bytes from ring buffer */
        while (ring_buf_get(&uart_rx_ring_buf, &byte, 1) > 0) {
            if (mavlink_parse_byte(&mavlink_parser, byte, &msg)) {
                /* Complete message received */
                LOG_INF("[MAVLink] Received message: id=%u, sys=%u, comp=%u, len=%u",
                       msg.msgid, msg.sysid, msg.compid, msg.len);
                
                uint8_t result = MAV_RESULT_UNSUPPORTED;
                
                switch (msg.msgid) {
                    case MAVLINK_MSG_ID_HEARTBEAT:
                        LOG_INF("[MAVLink] Heartbeat from sys=%u comp=%u",
                               msg.sysid, msg.compid);
                        /* No ACK needed for heartbeat */
                        break;
                        
                    case MAVLINK_MSG_ID_COMMAND_LONG:
                        /* Process command and send ACK */
                        result = process_mavlink_command(&msg);
                        
                        /* Extract command ID for ACK */
                        mavlink_command_long_t cmd;
                        memcpy(&cmd, msg.payload, sizeof(mavlink_command_long_t));
                        
                        /* Send ACK */
                        mavlink_send_command_ack(uart_dev, cmd.command, result,
                                                 msg.sysid, msg.compid);
                        
                        const char *result_str[] = {
                            "ACCEPTED", "TEMP_REJECTED", "DENIED", 
                            "UNSUPPORTED", "FAILED", "IN_PROGRESS"
                        };
                        LOG_INF("[MAVLink] Sent ACK: cmd=%u, result=%s",
                               cmd.command, result_str[result]);
                        break;
                        
                    default:
                        LOG_WRN("[MAVLink] Unhandled message ID: %u", msg.msgid);
                        break;
                }
            }
        }

        /* Send periodic heartbeat (1Hz) to drone/robotic controller */
        uint32_t current_time = k_uptime_get_32();
        if (current_time - last_heartbeat_time >= HEARTBEAT_PERIOD_MS) {
            mavlink_send_heartbeat(uart_dev);
            last_heartbeat_time = current_time;
            LOG_INF("[MAVLink] Heartbeat sent");
        } 
        
        k_msleep(MAVLINK_UPDATE_RATE_MS);
    }
}
```

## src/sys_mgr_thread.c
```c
/**
 * @file sysmgr_thread.c
 * @brief System Manager thread implementation
 * @details Processes system commands and manages state transitions
 */

#include <zephyr/kernel.h>
#include <zephyr/sys/printk.h>
#include <zephyr/logging/log.h>

#include "device_fsm.h"
#include "system_config.h"
#include "common_types.h"
#include "ipc_config.h"

#define LOG_LEVEL CONFIG_SYS_MGR_THREAD_LOG_LEVEL
LOG_MODULE_REGISTER(sys_mgr_thread);

/**
 * @brief System Manager Thread Main Loop
 * @details
 * - Processes system commands from queue
 * - Manages system state transitions
 * - Controls thread lifecycle
 * 
 * @param p1 Unused parameter
 * @param p2 Unused parameter
 * @param p3 Unused parameter
 */
void sys_mgr_thread(void *p1, void *p2, void *p3)
{
    sys_command_t cmd;

    ARG_UNUSED(p1);
    ARG_UNUSED(p2);
    ARG_UNUSED(p3);

    int ret;

    LOG_INF("System Manager Thread started");

    /* System Initialization */
    fsm_init();
    k_sleep(K_MSEC(100)); // Allow other threads to initialize

	fsm_event_handler(EVENT_INIT_DONE);
    LOG_INF("System initialized - entering IDLE state");

    while (1) {
        /* Update heartbeat */
        atomic_inc(&g_health.sys_mgr_heartbeat);

        /* Process commands from other threads */
        ret = k_msgq_get(&sys_cmd_queue, &cmd, K_MSEC(100));
        if (ret == 0) {
            LOG_INF("Received command: type=0x%02x", cmd.command);

            system_state_t sys_state = fsm_get_current_state();
            LOG_DBG("Current system state: %d", (int)sys_state);

            switch (cmd.command) {
                case CMD_START:
                    g_system_running = true;
                    LOG_INF("[Sys_Mgr] System STARTED\n");
                    /* TODO: Enable all subsystems */
                    break;

                case CMD_STOP:
                    g_system_running = false;
                    LOG_INF("[Sys_Mgr] System STOPPED\n");
                    /* TODO: Disable non-critical subsystems */
                    break;

                case CMD_STREAM_START:
                    LOG_INF("[Sys_Mgr] Video streaming STARTED\n");
                    /* TODO: Enable video pipeline */
                    break;

                case CMD_STREAM_STOP:
                    LOG_INF("[Sys_Mgr] Video streaming STOPPED\n");
                    /* TODO: Disable video pipeline */
                    break;

                case CMD_SHUTDOWN:
                    LOG_INF("[Sys_Mgr] System SHUTDOWN initiated\n");
                    /* TODO: Perform graceful shutdown */
                    /*       - Stop all threads */
                    /*       - Flush queues */
                    /*       - Save state if needed */
                    break;

                case CMD_ERROR:
                    LOG_INF("[Sys_Mgr] ERROR command received - initiating recovery\n");
                    /* TODO: Implement error recovery procedure */
                    /*       - Reset affected subsystems */
                    /*       - Clear error conditions */
                    /*       - Restart failed threads if needed */
                    break;

                default:
                    LOG_INF("Unknown command: 0x%02x", cmd.command);
                    break;
            }
        }

        k_msleep(SYSMGR_UPDATE_RATE_MS); // Low-frequency supervisory loop
    }
}
```
